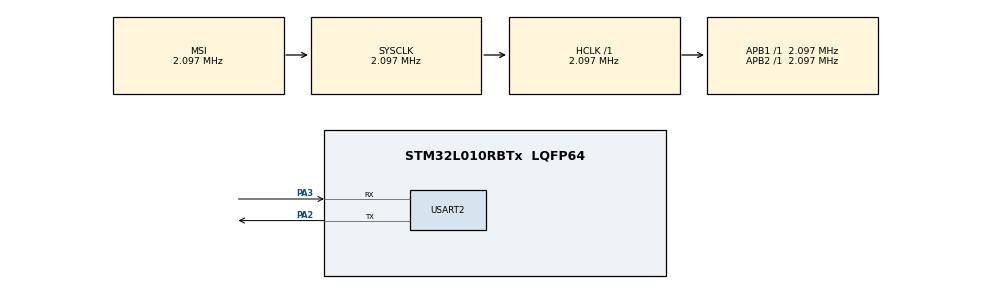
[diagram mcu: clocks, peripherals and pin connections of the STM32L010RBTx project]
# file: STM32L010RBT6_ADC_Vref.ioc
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ADC.ContinuousConvMode=DISABLE
ADC.ExternalTrigConv=ADC_SOFTWARE_START
ADC.SamplingTime=ADC_SAMPLETIME_160CYCLES_5
Mcu.Family=STM32L0
Mcu.Name=STM32L010RBTx
Mcu.Package=LQFP64
PA2.Mode=Asynchronous
PA2.Signal=USART2_TX
PA3.Mode=Asynchronous
PA3.Signal=USART2_RX
ProjectManager.HeapSize=0x200
ProjectManager.StackSize=0x400
ProjectManager.TargetToolchain=STM32CubeIDE
RCC.AHBFreq_Value=2097000
RCC.APB1Freq_Value=2097000
RCC.APB1TimFreq_Value=2097000
RCC.APB2Freq_Value=2097000
RCC.APB2TimFreq_Value=2097000
RCC.HSE_VALUE=8000000
RCC.HSI16_VALUE=16000000
RCC.HSI_VALUE=16000000
RCC.LSE_VALUE=32768
RCC.MSI_VALUE=2097000
RCC.SYSCLKFreq_VALUE=2097000
RCC.VCOOutputFreq_Value=48000000
USART2.VirtualMode-Asynchronous=VM_ASYNC
VP_ADC_Vref_Input.Mode=IN-Vrefint
board=custom

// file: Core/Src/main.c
/* USER CODE BEGIN Header */
/* USER CODE END Header */
#include "main.h"

/* USER CODE BEGIN Includes */
#include <stdio.h>
/* USER CODE END Includes */

/* USER CODE BEGIN PD */
#define VREFINT_CAL_ADDR ((uint16_t*) ((uint32_t) 0x1FF80078))
#define VREFINT_CAL_VOLTAGE 3.0f  // Nominal VREF+ voltage
#define ADC_RESOLUTION 4095.0f

/* USER CODE END PD */

ADC_HandleTypeDef hadc;

UART_HandleTypeDef huart2;

/* USER CODE BEGIN PV */
char msg[64];
uint16_t adc_raw;
/* USER CODE END PV */

void SystemClock_Config(void);
static void MX_GPIO_Init(void);
static void MX_ADC_Init(void);
static void MX_USART2_UART_Init(void);

int main(void)
{

  /* MCU Configuration--------------------------------------------------------*/

  /* Reset of all peripherals, Initializes the Flash interface and the Systick. */
  HAL_Init();

  /* Configure the system clock */
  SystemClock_Config();

  /* Initialize all configured peripherals */
  MX_GPIO_Init();
  MX_ADC_Init();
  MX_USART2_UART_Init();
  /* USER CODE BEGIN 2 */
  HAL_ADCEx_EnableVREFINT();  // Enable internal reference channel
  HAL_ADCEx_Calibration_Start(&hadc, ADC_SINGLE_ENDED);  // Calibrate ADC

  /* USER CODE END 2 */

  /* Infinite loop */
  /* USER CODE BEGIN WHILE */
  while (1)
    {
      ADC_ChannelConfTypeDef sConfig = {0};
      sConfig.Channel = ADC_CHANNEL_VREFINT;
      sConfig.Rank = ADC_RANK_CHANNEL_NUMBER;
      HAL_ADC_ConfigChannel(&hadc, &sConfig);

      HAL_ADC_Start(&hadc);
      HAL_ADC_PollForConversion(&hadc, HAL_MAX_DELAY);
      adc_raw = HAL_ADC_GetValue(&hadc);
      HAL_ADC_Stop(&hadc);

      float vref = VREFINT_CAL_VOLTAGE * ((float)(*VREFINT_CAL_ADDR) / (float)adc_raw);
      int len = snprintf(msg, sizeof(msg), "VREFINT => VDD: %.3f V\r\n", vref);
      HAL_UART_Transmit(&huart2, (uint8_t*)msg, len, HAL_MAX_DELAY);

      HAL_Delay(1000);
    }
    /* USER CODE END WHILE */

}

void SystemClock_Config(void)
{
  RCC_OscInitTypeDef RCC_OscInitStruct = {0};
  RCC_ClkInitTypeDef RCC_ClkInitStruct = {0};
  RCC_PeriphCLKInitTypeDef PeriphClkInit = {0};

  /** Configure the main internal regulator output voltage
  */
  __HAL_PWR_VOLTAGESCALING_CONFIG(PWR_REGULATOR_VOLTAGE_SCALE1);

  /** Initializes the RCC Oscillators according to the specified parameters
  * in the RCC_OscInitTypeDef structure.
  */
  RCC_OscInitStruct.OscillatorType = RCC_OSCILLATORTYPE_MSI;
  RCC_OscInitStruct.MSIState = RCC_MSI_ON;
  RCC_OscInitStruct.MSICalibrationValue = 0;
  RCC_OscInitStruct.MSIClockRange = RCC_MSIRANGE_5;
  RCC_OscInitStruct.PLL.PLLState = RCC_PLL_NONE;
  if (HAL_RCC_OscConfig(&RCC_OscInitStruct) != HAL_OK)
  {
    Error_Handler();
  }

  /** Initializes the CPU, AHB and APB buses clocks
  */
  RCC_ClkInitStruct.ClockType = RCC_CLOCKTYPE_HCLK|RCC_CLOCKTYPE_SYSCLK
                              |RCC_CLOCKTYPE_PCLK1|RCC_CLOCKTYPE_PCLK2;
  RCC_ClkInitStruct.SYSCLKSource = RCC_SYSCLKSOURCE_MSI;
  RCC_ClkInitStruct.AHBCLKDivider = RCC_SYSCLK_DIV1;
  RCC_ClkInitStruct.APB1CLKDivider = RCC_HCLK_DIV1;
  RCC_ClkInitStruct.APB2CLKDivider = RCC_HCLK_DIV1;

  if (HAL_RCC_ClockConfig(&RCC_ClkInitStruct, FLASH_LATENCY_0) != HAL_OK)
  {
    Error_Handler();
  }
  PeriphClkInit.PeriphClockSelection = RCC_PERIPHCLK_USART2;
  PeriphClkInit.Usart2ClockSelection = RCC_USART2CLKSOURCE_PCLK1;
  if (HAL_RCCEx_PeriphCLKConfig(&PeriphClkInit) != HAL_OK)
  {
    Error_Handler();
  }
}

static void MX_ADC_Init(void)
{

  ADC_ChannelConfTypeDef sConfig = {0};

  /** Configure the global features of the ADC (Clock, Resolution, Data Alignment and number of conversion)
  */
  hadc.Instance = ADC1;
  hadc.Init.OversamplingMode = DISABLE;
  hadc.Init.ClockPrescaler = ADC_CLOCK_SYNC_PCLK_DIV1;
  hadc.Init.Resolution = ADC_RESOLUTION_12B;
  hadc.Init.SamplingTime = ADC_SAMPLETIME_160CYCLES_5;
  hadc.Init.ScanConvMode = ADC_SCAN_DIRECTION_FORWARD;
  hadc.Init.DataAlign = ADC_DATAALIGN_RIGHT;
  hadc.Init.ContinuousConvMode = DISABLE;
  hadc.Init.DiscontinuousConvMode = DISABLE;
  hadc.Init.ExternalTrigConvEdge = ADC_EXTERNALTRIGCONVEDGE_NONE;
  hadc.Init.ExternalTrigConv = ADC_SOFTWARE_START;
  hadc.Init.DMAContinuousRequests = DISABLE;
  hadc.Init.EOCSelection = ADC_EOC_SINGLE_CONV;
  hadc.Init.Overrun = ADC_OVR_DATA_PRESERVED;
  hadc.Init.LowPowerAutoWait = DISABLE;
  hadc.Init.LowPowerFrequencyMode = ENABLE;
  hadc.Init.LowPowerAutoPowerOff = DISABLE;
  if (HAL_ADC_Init(&hadc) != HAL_OK)
  {
    Error_Handler();
  }

  /** Configure for the selected ADC regular channel to be converted.
  */
  sConfig.Channel = ADC_CHANNEL_VREFINT;
  sConfig.Rank = ADC_RANK_CHANNEL_NUMBER;
  if (HAL_ADC_ConfigChannel(&hadc, &sConfig) != HAL_OK)
  {
    Error_Handler();
  }

}

static void MX_USART2_UART_Init(void)
{

  huart2.Instance = USART2;
  huart2.Init.BaudRate = 115200;
  huart2.Init.WordLength = UART_WORDLENGTH_8B;
  huart2.Init.StopBits = UART_STOPBITS_1;
  huart2.Init.Parity = UART_PARITY_NONE;
  huart2.Init.Mode = UART_MODE_TX_RX;
  huart2.Init.HwFlowCtl = UART_HWCONTROL_NONE;
  huart2.Init.OverSampling = UART_OVERSAMPLING_16;
  huart2.Init.OneBitSampling = UART_ONE_BIT_SAMPLE_DISABLE;
  huart2.AdvancedInit.AdvFeatureInit = UART_ADVFEATURE_NO_INIT;
  if (HAL_UART_Init(&huart2) != HAL_OK)
  {
    Error_Handler();
  }

}

static void MX_GPIO_Init(void)
{

  /* GPIO Ports Clock Enable */
  __HAL_RCC_GPIOA_CLK_ENABLE();

}

void Error_Handler(void)
{
}
